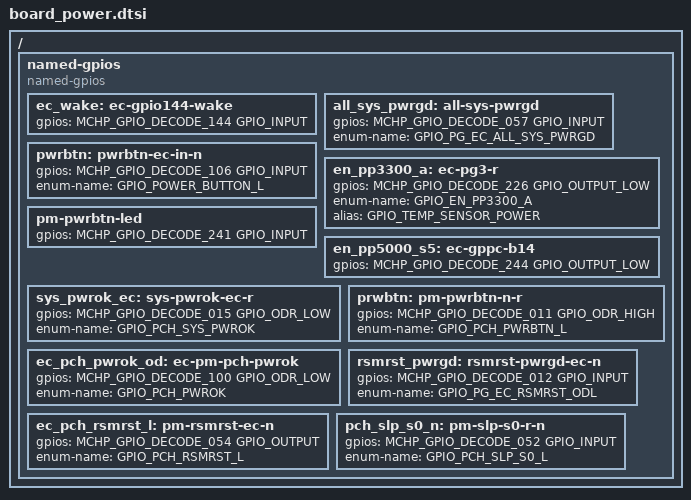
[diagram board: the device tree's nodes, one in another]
/* Copyright 2024 The ChromiumOS Authors
 * Use of this source code is governed by a BSD-style license that can be
 * found in the LICENSE file.
 */

#include "board.h"

/ {
	named-gpios {
		compatible = "named-gpios";

		ec_wake: ec-gpio144-wake {
			gpios = <MCHP_GPIO_DECODE_144 GPIO_INPUT>;
		};
		all_sys_pwrgd: all-sys-pwrgd {
			gpios = <MCHP_GPIO_DECODE_057 GPIO_INPUT>;
			enum-name = "GPIO_PG_EC_ALL_SYS_PWRGD";
		};
		pwrbtn: pwrbtn-ec-in-n {
			gpios = <MCHP_GPIO_DECODE_106 GPIO_INPUT>;
			enum-name = "GPIO_POWER_BUTTON_L";
		};
		en_pp3300_a: ec-pg3-r {
			gpios = <MCHP_GPIO_DECODE_226 GPIO_OUTPUT_LOW>;
			enum-name = "GPIO_EN_PP3300_A";
			alias = "GPIO_TEMP_SENSOR_POWER";
		};
		pm-pwrbtn-led {
			gpios = <MCHP_GPIO_DECODE_241 GPIO_INPUT>;
		};
		en_pp5000_s5: ec-gppc-b14 {
			gpios = <MCHP_GPIO_DECODE_244 GPIO_OUTPUT_LOW>;
		};
		sys_pwrok_ec: sys-pwrok-ec-r {
			gpios = <MCHP_GPIO_DECODE_015 GPIO_ODR_LOW>;
			enum-name = "GPIO_PCH_SYS_PWROK";
		};
		prwbtn: pm-pwrbtn-n-r {
			gpios = <MCHP_GPIO_DECODE_011 GPIO_ODR_HIGH>;
			enum-name = "GPIO_PCH_PWRBTN_L";
		};
		ec_pch_pwrok_od: ec-pm-pch-pwrok {
			gpios = <MCHP_GPIO_DECODE_100 GPIO_ODR_LOW>;
			enum-name = "GPIO_PCH_PWROK";
		};
		rsmrst_pwrgd: rsmrst-pwrgd-ec-n {
			gpios = <MCHP_GPIO_DECODE_012 GPIO_INPUT>;
			enum-name = "GPIO_PG_EC_RSMRST_ODL";
		};
		ec_pch_rsmrst_l: pm-rsmrst-ec-n {
			gpios = <MCHP_GPIO_DECODE_054 GPIO_OUTPUT>;
			enum-name = "GPIO_PCH_RSMRST_L";
		};
		pch_slp_s0_n: pm-slp-s0-r-n {
			gpios = <MCHP_GPIO_DECODE_052 GPIO_INPUT>;
			enum-name = "GPIO_PCH_SLP_S0_L";
		};
	};
};

#include "../ptlrvp/power_signals.dtsi"
